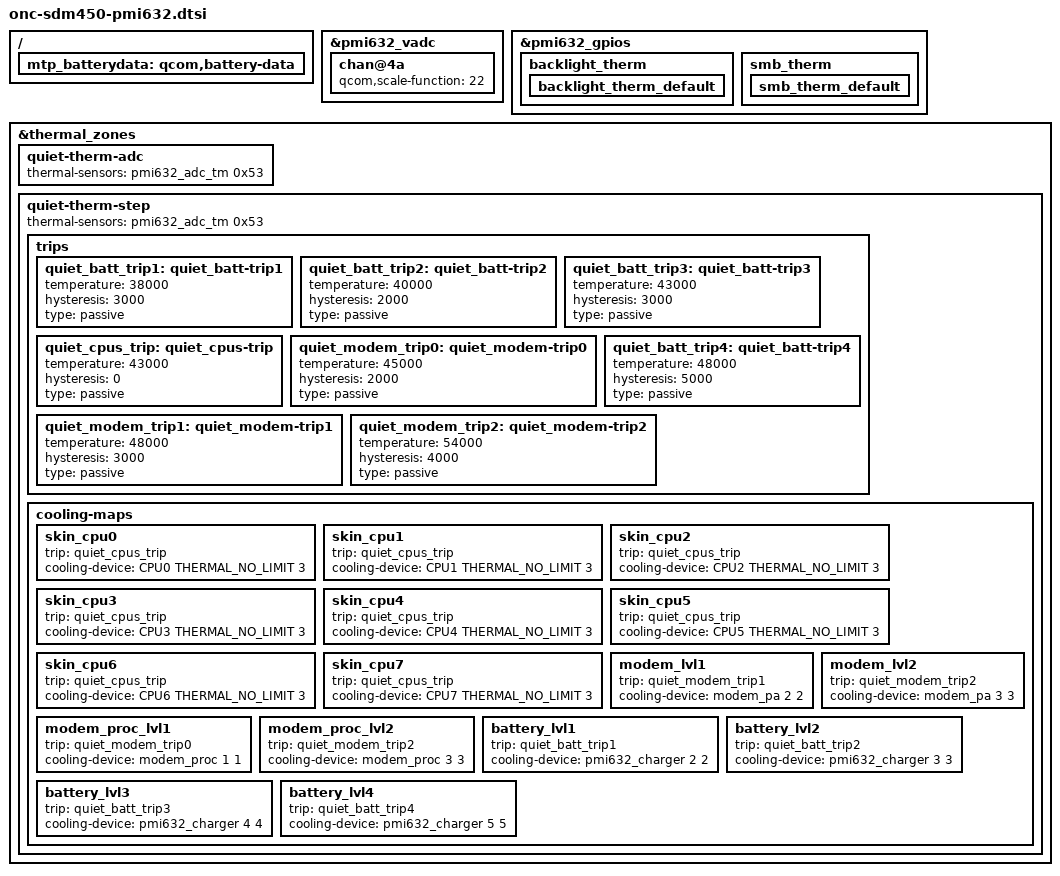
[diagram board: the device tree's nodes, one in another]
/*
 * Copyright (c) 2017-2019, The Linux Foundation. All rights reserved.
 * Copyright (C) 2020-2024 XiaoMi, Inc.
 *
 * This program is free software; you can redistribute it and/or modify
 * it under the terms of the GNU General Public License version 2 and
 * only version 2 as published by the Free Software Foundation.
 */

/ {
	mtp_batterydata: qcom,battery-data {
		/delete-node/ qcom,qg-battery-data@1;
		/delete-node/ qcom,qg-battery-data@2;
		#include "battery/qg-batterydata-atl-3900mah.dtsi"
		#include "battery/qg-batterydata-light-3900mah.dtsi"
		#include "battery/qg-batterydata-sunwoda-3900mah.dtsi"
		#include "battery/qg-batterydata-share-3900mah.dtsi"
	};
};

&pmi632_vadc {
	chan@4a {
		qcom,scale-function = <22>;
	};
};

&pmi632_gpios {
	backlight_therm {
		backlight_therm_default: backlight_therm_default {
		};
	};
	smb_therm {
		smb_therm_default: smb_therm_default {
		};
	};
};

&thermal_zones {
	backlight-therm-adc: quiet-therm-adc {
		thermal-sensors = <&pmi632_adc_tm 0x53>;
	};
	/delete-node/ quiet-therm-step;
	backlight-therm-step: quiet-therm-step {
		thermal-sensors = <&pmi632_adc_tm 0x53>;
		trips {
			quiet_batt_trip1: quiet_batt-trip1 { temperature = <38000>; hysteresis = <3000>; type = "passive"; };
			quiet_batt_trip2: quiet_batt-trip2 { temperature = <40000>; hysteresis = <2000>; type = "passive"; };
			quiet_batt_trip3: quiet_batt-trip3 { temperature = <43000>; hysteresis = <3000>; type = "passive"; };
			quiet_cpus_trip: quiet_cpus-trip { temperature = <43000>; hysteresis = <0>; type = "passive"; };
			quiet_modem_trip0: quiet_modem-trip0 { temperature = <45000>; hysteresis = <2000>; type = "passive"; };
			quiet_batt_trip4: quiet_batt-trip4 { temperature = <48000>; hysteresis = <5000>; type = "passive"; };
			quiet_modem_trip1: quiet_modem-trip1 { temperature = <48000>; hysteresis = <3000>; type = "passive"; };
			quiet_modem_trip2: quiet_modem-trip2 { temperature = <54000>; hysteresis = <4000>; type = "passive"; };
		};
		cooling-maps {
			skin_cpu0 { trip = <&quiet_cpus_trip>; cooling-device = <&CPU0 THERMAL_NO_LIMIT 3>; };
			skin_cpu1 { trip = <&quiet_cpus_trip>; cooling-device = <&CPU1 THERMAL_NO_LIMIT 3>; };
			skin_cpu2 { trip = <&quiet_cpus_trip>; cooling-device = <&CPU2 THERMAL_NO_LIMIT 3>; };
			skin_cpu3 { trip = <&quiet_cpus_trip>; cooling-device = <&CPU3 THERMAL_NO_LIMIT 3>; };
			skin_cpu4 { trip = <&quiet_cpus_trip>; cooling-device = <&CPU4 THERMAL_NO_LIMIT 3>; };
			skin_cpu5 { trip = <&quiet_cpus_trip>; cooling-device = <&CPU5 THERMAL_NO_LIMIT 3>; };
			skin_cpu6 { trip = <&quiet_cpus_trip>; cooling-device = <&CPU6 THERMAL_NO_LIMIT 3>; };
			skin_cpu7 { trip = <&quiet_cpus_trip>; cooling-device = <&CPU7 THERMAL_NO_LIMIT 3>; };
			modem_lvl1 { trip = <&quiet_modem_trip1>; cooling-device = <&modem_pa 2 2>; };
			modem_lvl2 { trip = <&quiet_modem_trip2>; cooling-device = <&modem_pa 3 3>; };
			modem_proc_lvl1 { trip = <&quiet_modem_trip0>; cooling-device = <&modem_proc 1 1>; };
			modem_proc_lvl2 { trip = <&quiet_modem_trip2>; cooling-device = <&modem_proc 3 3>; };
			battery_lvl1 { trip = <&quiet_batt_trip1>; cooling-device = <&pmi632_charger 2 2>; };
			battery_lvl2 { trip = <&quiet_batt_trip2>; cooling-device = <&pmi632_charger 3 3>; };
			battery_lvl3 { trip = <&quiet_batt_trip3>; cooling-device = <&pmi632_charger 4 4>; };
			battery_lvl4 { trip = <&quiet_batt_trip4>; cooling-device = <&pmi632_charger 5 5>; };
		};
	};
};
